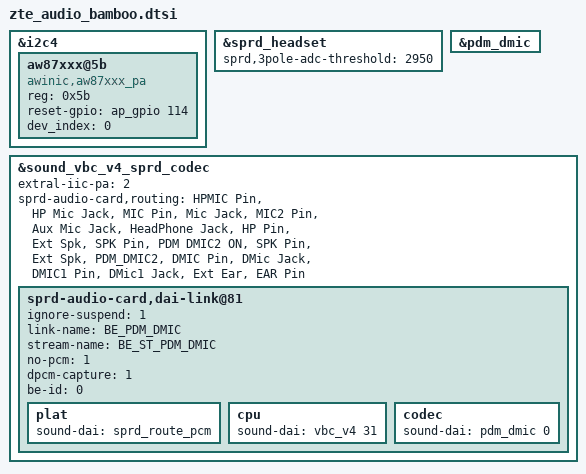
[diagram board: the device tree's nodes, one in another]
&i2c4 {
	status = "okay";
	#address-cells = <1>;
	#size-cells = <0>;
	aw87xxx@5b {
		compatible = "awinic,aw87xxx_pa";
		reg = <0x5b>;
		reset-gpio = <&ap_gpio  114 0>;
		dev_index = <0>;
		status = "okay";
	};
};

&sprd_headset {
	status = "okay";
	sprd,3pole-adc-threshold = <2950>;
};

&pdm_dmic {
	status = "okay";
};

&sound_vbc_v4_sprd_codec {
	status = "okay";
	extral-iic-pa = <2>;

	sprd-audio-card,routing =
		"HPMIC Pin", "HP Mic Jack",
		"MIC Pin", "Mic Jack",
		"MIC2 Pin", "Aux Mic Jack",
		"HeadPhone Jack", "HP Pin",
		"Ext Spk", "SPK Pin",
		"PDM DMIC2 ON", "SPK Pin",
		"Ext Spk", "PDM_DMIC2",
		"DMIC Pin", "DMic Jack",
		"DMIC1 Pin", "DMic1 Jack",
		"Ext Ear", "EAR Pin";

	/* 63: pdm dmic */
	sprd-audio-card,dai-link@81 {
		ignore-suspend = <1>;
		link-name = "BE_PDM_DMIC";
		stream-name = "BE_ST_PDM_DMIC";
		no-pcm = <1>;
		dpcm-capture = <1>;
		be-id = <0>;
		//dai-format = "i2s";
		plat {
			sound-dai = <&sprd_route_pcm>;
		};
		cpu {
			sound-dai = <&vbc_v4 31>;
		};
		codec {
			sound-dai = <&pdm_dmic 0>;
		};
	};
};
